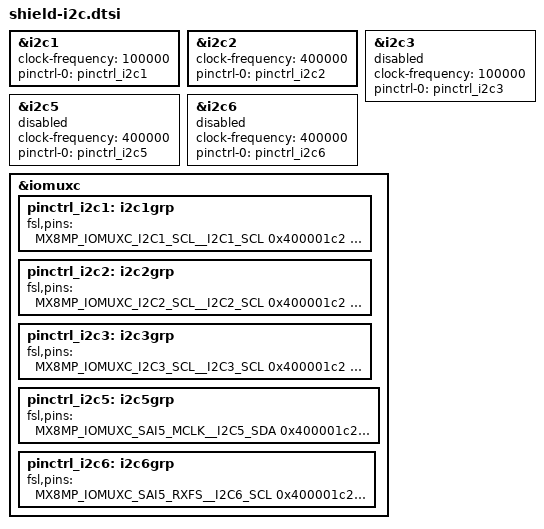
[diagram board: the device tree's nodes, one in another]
// SPDX-License-Identifier: (GPL-2.0+ OR MIT)
/*
 * Copyright 2025 CriticalShift
 */

&i2c1 {
	clock-frequency = <100000>;
	pinctrl-names = "default";
	pinctrl-0 = <&pinctrl_i2c1>;
	status = "okay";
};

&i2c2 {
	clock-frequency = <400000>;
	pinctrl-names = "default";
	pinctrl-0 = <&pinctrl_i2c2>;
	status = "okay";
};

&i2c3 {
	clock-frequency = <100000>;
	pinctrl-names = "default";
	pinctrl-0 = <&pinctrl_i2c3>;
	status = "disabled";
};

&i2c5 {
	clock-frequency = <400000>;
	pinctrl-names = "default";
	pinctrl-0 = <&pinctrl_i2c5>;
	status = "disabled";
};

&i2c6 {
	clock-frequency = <400000>;
	pinctrl-names = "default";
	pinctrl-0 = <&pinctrl_i2c6>;
	status = "disabled";
};

&iomuxc {
	pinctrl_i2c1: i2c1grp {
		fsl,pins = <
			MX8MP_IOMUXC_I2C1_SCL__I2C1_SCL						0x400001c2
			MX8MP_IOMUXC_I2C1_SDA__I2C1_SDA						0x400001c2
		>;
	};

	pinctrl_i2c2: i2c2grp {
		fsl,pins = <
			MX8MP_IOMUXC_I2C2_SCL__I2C2_SCL						0x400001c2
			MX8MP_IOMUXC_I2C2_SDA__I2C2_SDA						0x400001c2
		>;
	};

	pinctrl_i2c3: i2c3grp {
		fsl,pins = <
			MX8MP_IOMUXC_I2C3_SCL__I2C3_SCL						0x400001c2
			MX8MP_IOMUXC_I2C3_SDA__I2C3_SDA						0x400001c2
		>;
	};

	pinctrl_i2c5: i2c5grp {
		fsl,pins = <
			MX8MP_IOMUXC_SAI5_MCLK__I2C5_SDA					0x400001c2
			MX8MP_IOMUXC_SAI5_RXD0__I2C5_SCL					0x400001c2
		>;
	};

	pinctrl_i2c6: i2c6grp {
		fsl,pins = <
			MX8MP_IOMUXC_SAI5_RXFS__I2C6_SCL					0x400001c2
			MX8MP_IOMUXC_SAI5_RXC__I2C6_SDA						0x400001c2
		>;
	};
};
